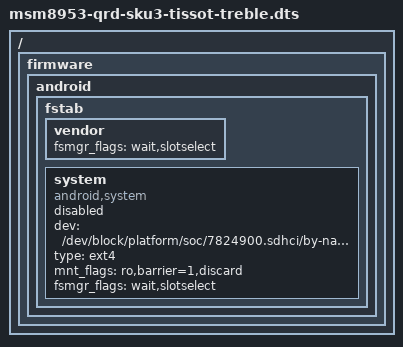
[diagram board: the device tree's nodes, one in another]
/*
 * Copyright (c) 2015-2017, The Linux Foundation. All rights reserved.
 * SPDX-License-Identifier: GPL-2.0-only
 */

/dts-v1/;

#include "msm8953-qrd-sku3-tissot-common.dtsi"

/ {
	firmware {
		android {
			fstab {
				vendor {
					fsmgr_flags = "wait,slotselect";
					status = "ok";
				};
				system {
					compatible = "android,system";
					dev = "/dev/block/platform/soc/7824900.sdhci/by-name/system";
					type = "ext4";
					mnt_flags = "ro,barrier=1,discard";
					fsmgr_flags = "wait,slotselect";
					status = "disable";
				};
			};
		};
	};
};
